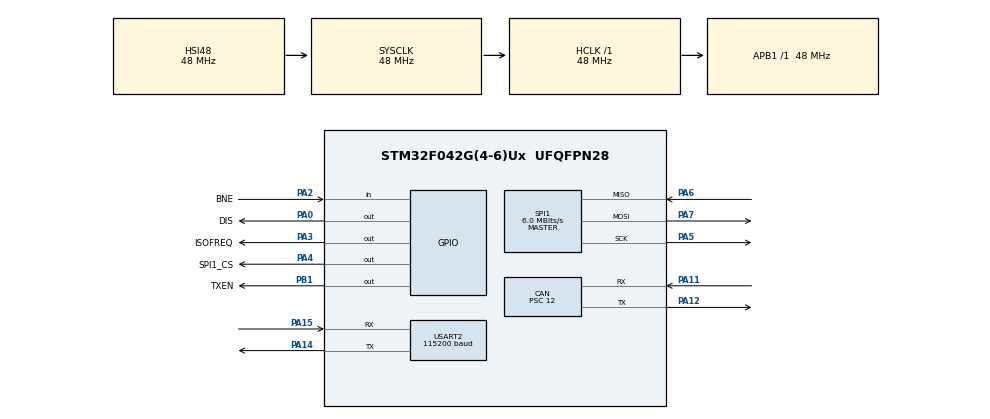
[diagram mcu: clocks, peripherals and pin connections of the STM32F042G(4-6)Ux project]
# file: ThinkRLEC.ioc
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CAN.BS1=CAN_BS1_6TQ
CAN.CalculateBaudRate=500000
CAN.CalculateTimeBit=2000
CAN.CalculateTimeQuantum=250.0
CAN.Prescaler=12
IWDG.Prescaler=IWDG_PRESCALER_16
Mcu.Family=STM32F0
Mcu.Name=STM32F042G(4-6)Ux
Mcu.Package=UFQFPN28
NVIC.CEC_CAN_IRQn=true\:0\:0\:false\:false\:true\:true\:true\:true
PA0.GPIO_Label=DIS
PA0.Signal=GPIO_Output
PA11.Mode=CAN_Activate
PA11.Signal=CAN_RX
PA12.Mode=CAN_Activate
PA12.Signal=CAN_TX
PA14.Mode=Asynchronous
PA14.Signal=USART2_TX
PA15.Mode=Asynchronous
PA15.Signal=USART2_RX
PA2.GPIO_Label=BNE
PA2.Signal=GPIO_Input
PA3.GPIO_Label=ISOFREQ
PA3.Signal=GPIO_Output
PA4.GPIO_Label=SPI1_CS
PA4.GPIO_Speed=GPIO_SPEED_FREQ_HIGH
PA4.PinState=GPIO_PIN_RESET
PA4.Signal=GPIO_Output
PA5.Mode=Full_Duplex_Master
PA5.Signal=SPI1_SCK
PA6.Mode=Full_Duplex_Master
PA6.Signal=SPI1_MISO
PA7.Mode=Full_Duplex_Master
PA7.Signal=SPI1_MOSI
PB1.GPIO_Label=TXEN
PB1.Signal=GPIO_Output
ProjectManager.HeapSize=0x200
ProjectManager.StackSize=0x400
ProjectManager.TargetToolchain=STM32CubeIDE
RCC.AHBFreq_Value=48000000
RCC.APB1Freq_Value=48000000
RCC.APB1TimFreq_Value=48000000
RCC.HCLKFreq_Value=48000000
RCC.SYSCLKFreq_VALUE=48000000
RCC.SYSCLKSource=RCC_SYSCLKSOURCE_HSI48
SPI1.BaudRatePrescaler=SPI_BAUDRATEPRESCALER_8
SPI1.CLKPhase=SPI_PHASE_2EDGE
SPI1.CRCCalculation=SPI_CRCCALCULATION_DISABLE
SPI1.CalculateBaudRate=6.0 MBits/s
SPI1.DataSize=SPI_DATASIZE_8BIT
SPI1.Direction=SPI_DIRECTION_2LINES
SPI1.Mode=SPI_MODE_MASTER
SPI1.VirtualType=VM_MASTER
USART2.BaudRate=115200
USART2.VirtualMode-Asynchronous=VM_ASYNC
VP_IWDG_VS_IWDG.Mode=IWDG_Activate
VP_SYS_VS_PINREMAP.Mode=PINREMAP
board=custom

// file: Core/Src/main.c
/* USER CODE BEGIN Header */
/**
  ******************************************************************************
  * @file           : main.c
  * @brief          : Main program body
  ******************************************************************************
  * @attention
  *
  * This code is mainly autogenerated
  *
  *
  ******************************************************************************
  */
/* USER CODE END Header */
#include "main.h"

CAN_HandleTypeDef hcan;

IWDG_HandleTypeDef hiwdg;

SPI_HandleTypeDef hspi1;

UART_HandleTypeDef huart2;

void SystemClock_Config(void);
static void MX_GPIO_Init(void);
static void MX_CAN_Init(void);
static void MX_SPI1_Init(void);
static void MX_USART2_UART_Init(void);
static void MX_IWDG_Init(void);
/* USER CODE BEGIN PFP */
void realmain(void);

/* USER CODE END PFP */

/* USER CODE BEGIN 0 */

/**
  * define putchar and write here so don't need syscall
  * also redirects to uart
  */
int __io_putchar(int ch)
{
	HAL_UART_Transmit(&huart2, (uint8_t *)&ch, 1, 0xFFFF);

	return ch;
}

int _write(int file, char *ptr, int len)
{
	while(len--) __io_putchar( *ptr++ );

	return len;
}

/* these just to not have annoying linker warnings */
/* also makes code size 72 bytes smaller for some reason */
void _close(void) { };
void _fstat(void) { };
void _isatty(void) { };
void _read(void) { };
void _lseek(void) { };

/* USER CODE END 0 */

int main(void)
{

  /* MCU Configuration--------------------------------------------------------*/

  /* Reset of all peripherals, Initializes the Flash interface and the Systick. */
  HAL_Init();

  /* Configure the system clock */
  SystemClock_Config();

  /* Initialize all configured peripherals */
  MX_GPIO_Init();
  MX_CAN_Init();
  MX_SPI1_Init();
  MX_USART2_UART_Init();
  MX_IWDG_Init();
  /* USER CODE BEGIN 2 */

  realmain();

  /* USER CODE END 2 */

  /* Infinite loop */
  while (1)
  {

  }
}

void SystemClock_Config(void)
{
  RCC_OscInitTypeDef RCC_OscInitStruct = {0};
  RCC_ClkInitTypeDef RCC_ClkInitStruct = {0};

  /** Initializes the RCC Oscillators according to the specified parameters
  * in the RCC_OscInitTypeDef structure.
  */
  RCC_OscInitStruct.OscillatorType = RCC_OSCILLATORTYPE_HSI48|RCC_OSCILLATORTYPE_LSI;
  RCC_OscInitStruct.HSI48State = RCC_HSI48_ON;
  RCC_OscInitStruct.LSIState = RCC_LSI_ON;
  RCC_OscInitStruct.PLL.PLLState = RCC_PLL_NONE;
  if (HAL_RCC_OscConfig(&RCC_OscInitStruct) != HAL_OK)
  {
    Error_Handler();
  }

  /** Initializes the CPU, AHB and APB buses clocks
  */
  RCC_ClkInitStruct.ClockType = RCC_CLOCKTYPE_HCLK|RCC_CLOCKTYPE_SYSCLK
                              |RCC_CLOCKTYPE_PCLK1;
  RCC_ClkInitStruct.SYSCLKSource = RCC_SYSCLKSOURCE_HSI48;
  RCC_ClkInitStruct.AHBCLKDivider = RCC_SYSCLK_DIV1;
  RCC_ClkInitStruct.APB1CLKDivider = RCC_HCLK_DIV1;

  if (HAL_RCC_ClockConfig(&RCC_ClkInitStruct, FLASH_LATENCY_1) != HAL_OK)
  {
    Error_Handler();
  }
}

static void MX_CAN_Init(void)
{

  hcan.Instance = CAN;
  hcan.Init.Prescaler = 12;
  hcan.Init.Mode = CAN_MODE_NORMAL;
  hcan.Init.SyncJumpWidth = CAN_SJW_1TQ;
  hcan.Init.TimeSeg1 = CAN_BS1_6TQ;
  hcan.Init.TimeSeg2 = CAN_BS2_1TQ;
  hcan.Init.TimeTriggeredMode = DISABLE;
  hcan.Init.AutoBusOff = DISABLE;
  hcan.Init.AutoWakeUp = DISABLE;
  hcan.Init.AutoRetransmission = DISABLE;
  hcan.Init.ReceiveFifoLocked = DISABLE;
  hcan.Init.TransmitFifoPriority = DISABLE;
  if (HAL_CAN_Init(&hcan) != HAL_OK)
  {
    Error_Handler();
  }

}

static void MX_IWDG_Init(void)
{

  hiwdg.Instance = IWDG;
  hiwdg.Init.Prescaler = IWDG_PRESCALER_16;
  hiwdg.Init.Window = 4095;
  hiwdg.Init.Reload = 4095;
  if (HAL_IWDG_Init(&hiwdg) != HAL_OK)
  {
    Error_Handler();
  }

}

static void MX_SPI1_Init(void)
{

  /* SPI1 parameter configuration*/
  hspi1.Instance = SPI1;
  hspi1.Init.Mode = SPI_MODE_MASTER;
  hspi1.Init.Direction = SPI_DIRECTION_2LINES;
  hspi1.Init.DataSize = SPI_DATASIZE_8BIT;
  hspi1.Init.CLKPolarity = SPI_POLARITY_LOW;
  hspi1.Init.CLKPhase = SPI_PHASE_2EDGE;
  hspi1.Init.NSS = SPI_NSS_SOFT;
  hspi1.Init.BaudRatePrescaler = SPI_BAUDRATEPRESCALER_8;
  hspi1.Init.FirstBit = SPI_FIRSTBIT_MSB;
  hspi1.Init.TIMode = SPI_TIMODE_DISABLE;
  hspi1.Init.CRCCalculation = SPI_CRCCALCULATION_DISABLE;
  hspi1.Init.CRCPolynomial = 7;
  hspi1.Init.CRCLength = SPI_CRC_LENGTH_DATASIZE;
  hspi1.Init.NSSPMode = SPI_NSS_PULSE_DISABLE;
  if (HAL_SPI_Init(&hspi1) != HAL_OK)
  {
    Error_Handler();
  }

}

static void MX_USART2_UART_Init(void)
{

  huart2.Instance = USART2;
  huart2.Init.BaudRate = 115200;
  huart2.Init.WordLength = UART_WORDLENGTH_8B;
  huart2.Init.StopBits = UART_STOPBITS_1;
  huart2.Init.Parity = UART_PARITY_NONE;
  huart2.Init.Mode = UART_MODE_TX_RX;
  huart2.Init.HwFlowCtl = UART_HWCONTROL_NONE;
  huart2.Init.OverSampling = UART_OVERSAMPLING_16;
  huart2.Init.OneBitSampling = UART_ONE_BIT_SAMPLE_DISABLE;
  huart2.AdvancedInit.AdvFeatureInit = UART_ADVFEATURE_NO_INIT;
  if (HAL_UART_Init(&huart2) != HAL_OK)
  {
    Error_Handler();
  }

}

static void MX_GPIO_Init(void)
{
  GPIO_InitTypeDef GPIO_InitStruct = {0};

  /* GPIO Ports Clock Enable */
  __HAL_RCC_GPIOA_CLK_ENABLE();
  __HAL_RCC_GPIOB_CLK_ENABLE();

  /*Configure GPIO pin Output Level */
  HAL_GPIO_WritePin(GPIOA, DIS_Pin|ISOFREQ_Pin|SPI1_CS_Pin, GPIO_PIN_RESET);

  /*Configure GPIO pin Output Level */
  HAL_GPIO_WritePin(TXEN_GPIO_Port, TXEN_Pin, GPIO_PIN_RESET);

  /*Configure GPIO pins : DIS_Pin ISOFREQ_Pin */
  GPIO_InitStruct.Pin = DIS_Pin|ISOFREQ_Pin;
  GPIO_InitStruct.Mode = GPIO_MODE_OUTPUT_PP;
  GPIO_InitStruct.Pull = GPIO_NOPULL;
  GPIO_InitStruct.Speed = GPIO_SPEED_FREQ_LOW;
  HAL_GPIO_Init(GPIOA, &GPIO_InitStruct);

  /*Configure GPIO pin : BNE_Pin */
  GPIO_InitStruct.Pin = BNE_Pin;
  GPIO_InitStruct.Mode = GPIO_MODE_INPUT;
  GPIO_InitStruct.Pull = GPIO_NOPULL;
  HAL_GPIO_Init(BNE_GPIO_Port, &GPIO_InitStruct);

  /*Configure GPIO pin : SPI1_CS_Pin */
  GPIO_InitStruct.Pin = SPI1_CS_Pin;
  GPIO_InitStruct.Mode = GPIO_MODE_OUTPUT_PP;
  GPIO_InitStruct.Pull = GPIO_NOPULL;
  GPIO_InitStruct.Speed = GPIO_SPEED_FREQ_HIGH;
  HAL_GPIO_Init(SPI1_CS_GPIO_Port, &GPIO_InitStruct);

  /*Configure GPIO pin : TXEN_Pin */
  GPIO_InitStruct.Pin = TXEN_Pin;
  GPIO_InitStruct.Mode = GPIO_MODE_OUTPUT_PP;
  GPIO_InitStruct.Pull = GPIO_NOPULL;
  GPIO_InitStruct.Speed = GPIO_SPEED_FREQ_LOW;
  HAL_GPIO_Init(TXEN_GPIO_Port, &GPIO_InitStruct);

}

void Error_Handler(void)
{
  __disable_irq();
  while (1)
  {
  }
}
